# STM32N657 register map
File version: 1.0
CPU: CM55 r0p1, little endian, no MPU, FPU, vendor SysTick, 8 interrupt priority bits
Registers are 32-bit, read-write, reset 0x0 unless marked. A register's access mark holds for its fields unless they carry their own. Offsets are from the block's base; [hi:lo] are bit positions; {n}, {i} and the like mark numbered series.

## ICACHE — Texture cache
Base 0x48035000
Same registers: ICACHE_S 0x58035000
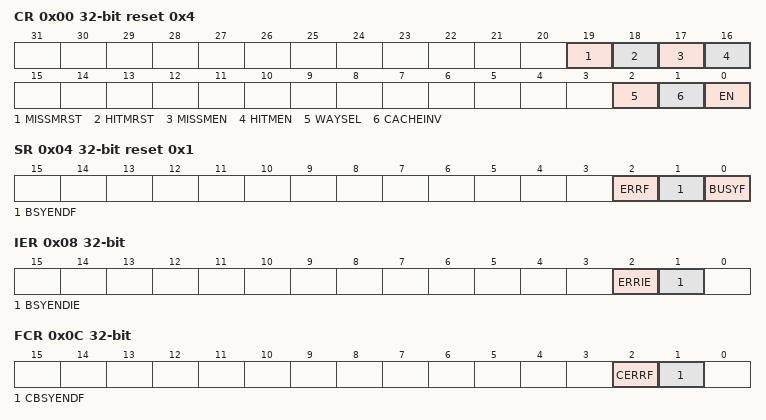
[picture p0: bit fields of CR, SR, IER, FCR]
0x00 CR access per field reset 0x4 — ICACHE control register
  [19] MISSMRST rw — miss monitor reset
  [18] HITMRST rw — hit monitor reset
  [17] MISSMEN rw — miss monitor enable
  [16] HITMEN rw — hit monitor enable
  [2] WAYSEL rw — cache associativity mode selection
  [1] CACHEINV wo — cache invalidation
  [0] EN rw — enable
0x04 SR ro reset 0x1 — ICACHE status register
  [2] ERRF — cache error flag
  [1] BSYENDF — busy end flag
  [0] BUSYF — busy flag
0x08 IER — ICACHE interrupt enable register
  [2] ERRIE — interrupt enable on cache error
  [1] BSYENDIE — interrupt enable on busy end
0x0C FCR wo — ICACHE flag clear register
  [2] CERRF — clear cache error flag
  [1] CBSYENDF — clear busy end flag
0x10 HMONR ro — ICACHE hit monitor register
  [31:0] HITMON — cache hit monitor counter
0x14 MMONR ro — ICACHE miss monitor register
  [15:0] MISSMON — cache miss monitor counter

## IWDG — Independent watchdog
Base 0x46004800
Same registers: IWDG_S 0x56004800
0x00 KR wo — IWDG key register
  [15:0] KEY — Key value (write only, read 0x0000)
0x04 PR — IWDG prescaler register
  [3:0] PR — Prescaler divider
0x08 RLR reset 0xFFF — IWDG reload register
  [11:0] RL — Watchdog counter reload value
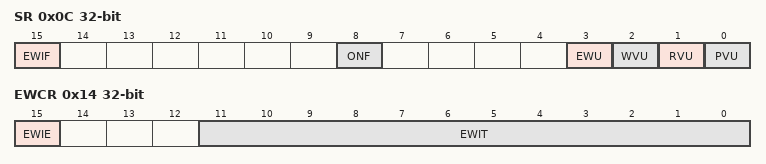
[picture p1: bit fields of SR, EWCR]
0x0C SR ro — IWDG status register
  [15] EWIF — Watchdog early interrupt flag
  [8] ONF — Watchdog enable status bit
  [3] EWU — Watchdog interrupt comparator value update
  [2] WVU — Watchdog counter window value update
  [1] RVU — Watchdog counter reload value update
  [0] PVU — Watchdog prescaler value update
0x10 WINR reset 0xFFF — IWDG window register
  [11:0] WIN — Watchdog counter window value
0x14 EWCR — IWDG early wake-up interrupt register
  [15] EWIE — Watchdog early interrupt enable
  [11:0] EWIT — Watchdog counter window value
0x18 ICR — IWDG interrupt clear register
  [15] EWIC — Watchdog early interrupt acknowledge

## MDIOS — Management data input/output
Base 0x40009400
Same registers: MDIOS_S 0x50009400
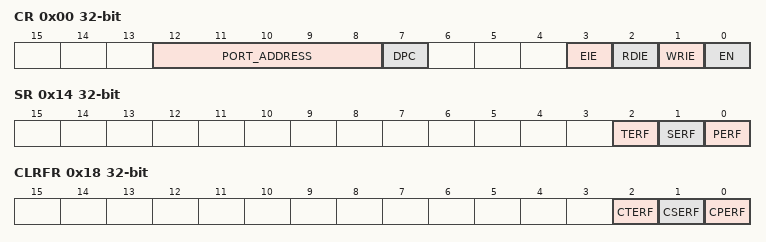
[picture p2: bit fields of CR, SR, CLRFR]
0x00 CR — MDIOS configuration register
  [12:8] PORT_ADDRESS — slave address
  [7] DPC — disable preamble check
  [3] EIE — error interrupt enable
  [2] RDIE — register read interrupt enable
  [1] WRIE — register write interrupt enable
  [0] EN — peripheral enable
0x04 WRFR ro — MDIOS write flag register
  [31:0] WRF — write flags for MDIOS registers 0 to 31.
0x08 CWRFR — MDIOS clear write flag register
  [31:0] CWRF — clear the write flag
0x0C RDFR ro — MDIOS read flag register
  [31:0] RDF — read flags for MDIOS registers 0 to 31.
0x10 CRDFR — MDIOS clear read flag register
  [31:0] CRDF — clear the read flag
0x14 SR ro — MDIOS status register
  [2] TERF — turnaround error flag
  [1] SERF — start error flag
  [0] PERF — preamble error flag
0x18 CLRFR — MDIOS clear flag register
  [2] CTERF — clear the turnaround error flag
  [1] CSERF — clear the start error flag
  [0] CPERF — clear the preamble error flag
{0x100+4i} DINR{i} ro (i=0..31) — MDIOS input data register {i}
  [15:0] DIN — input data received from MDIO master during write frames
{0x180+4i} DOUTR{i} (i=0..31) — MDIOS output data register {i}
  [15:0] DOUT — output data sent to MDIO Master during read frames

## PKA — Public key accelerator
Base 0x44022000
Same registers: PKA_S 0x54022000
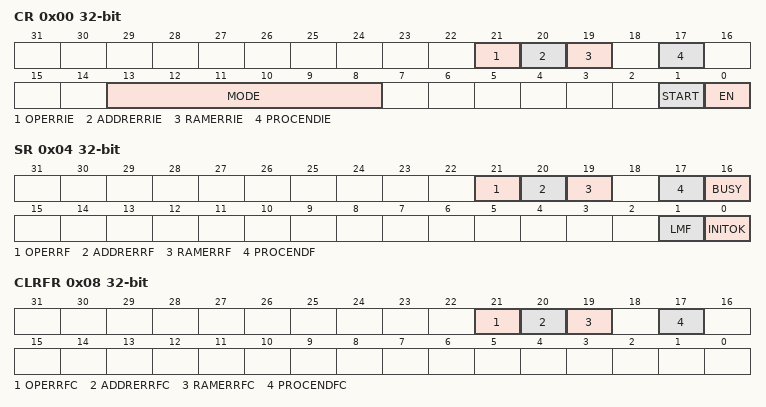
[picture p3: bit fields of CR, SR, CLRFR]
0x00 CR — PKA control register
  [21] OPERRIE — Operation error interrupt enable
  [20] ADDRERRIE — Address error interrupt enable
  [19] RAMERRIE — RAM error interrupt enable
  [17] PROCENDIE — End of operation interrupt enable
  [13:8] MODE — PKA operation code
  [1] START — start the operation
  [0] EN — PKA enable.
0x04 SR ro — PKA status register
  [21] OPERRF — Operation error flag
  [20] ADDRERRF — Address error flag
  [19] RAMERRF — PKA RAM error flag
  [17] PROCENDF — PKA End of Operation flag
  [16] BUSY — PKA operation is in progress
  [1] LMF — Limited mode flag
  [0] INITOK — PKA initialization OK
0x08 CLRFR wo — PKA clear flag register
  [21] OPERRFC — Clear operation error flag
  [20] ADDRERRFC — Clear address error flag
  [19] RAMERRFC — Clear PKA RAM error flag
  [17] PROCENDFC — Clear PKA End of Operation flag
